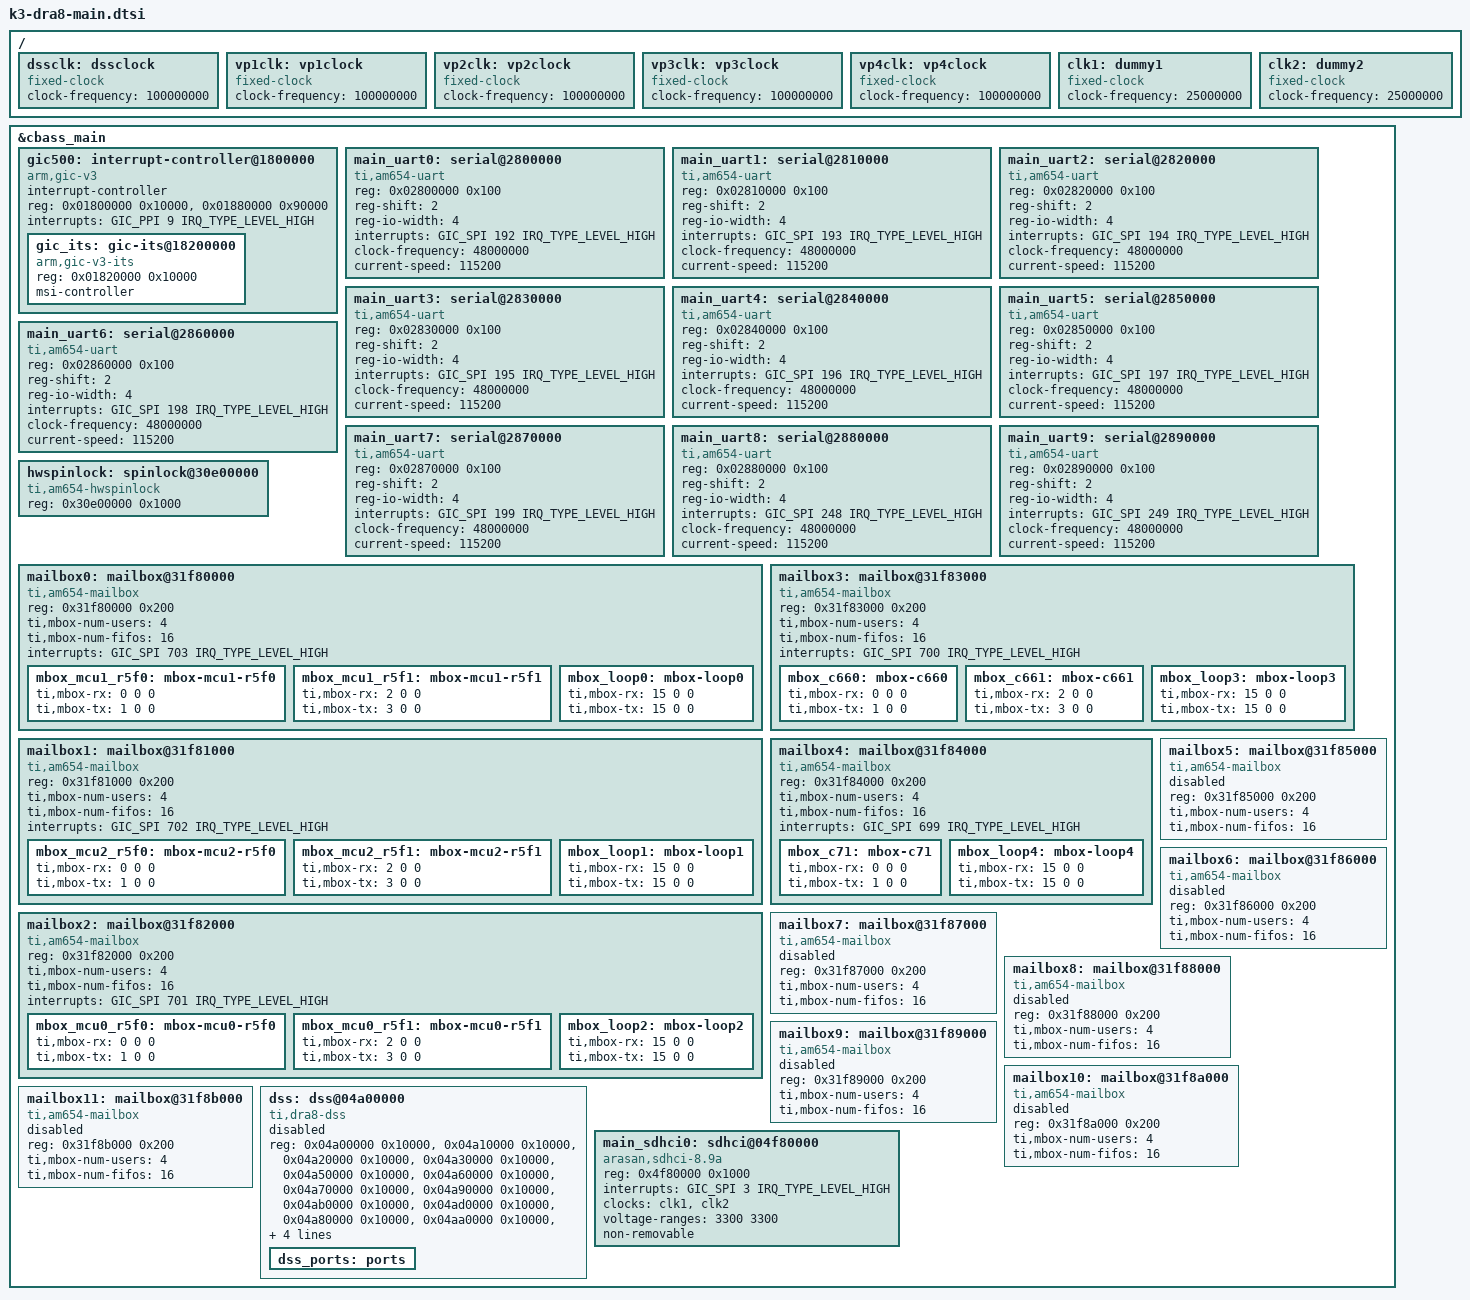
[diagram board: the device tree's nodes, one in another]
// SPDX-License-Identifier: GPL-2.0
/*
 * Device Tree Source for DRA8 SoC Family Main Domain peripherals
 *
 * Copyright (C) 2016-2018 Texas Instruments Incorporated - http://www.ti.com/
 */

/ {
	dssclk: dssclock {
		compatible = "fixed-clock";
		#clock-cells = <0>;
		clock-frequency = <100000000>;
	};

	vp1clk: vp1clock {
		compatible = "fixed-clock";
		#clock-cells = <0>;
		clock-frequency = <100000000>;
	};

	vp2clk: vp2clock {
		compatible = "fixed-clock";
		#clock-cells = <0>;
		clock-frequency = <100000000>;
	};

	vp3clk: vp3clock {
		compatible = "fixed-clock";
		#clock-cells = <0>;
		clock-frequency = <100000000>;
	};

	vp4clk: vp4clock {
		compatible = "fixed-clock";
		#clock-cells = <0>;
		clock-frequency = <100000000>;
	};

	clk1: dummy1 {
		compatible = "fixed-clock";
		#clock-cells = <0>;
		clock-frequency = <25000000>;
	};

	clk2: dummy2 {
		compatible = "fixed-clock";
		#clock-cells = <0>;
		clock-frequency = <25000000>;
	};
};

&cbass_main {
	gic500: interrupt-controller@1800000 {
		compatible = "arm,gic-v3";
		#address-cells = <1>;
		#size-cells = <1>;
		ranges;
		#interrupt-cells = <3>;
		interrupt-controller;
		reg = <0x01800000 0x10000>,	/* GICD */
		      <0x01880000 0x90000>;	/* GICR */
		/*
		 * vcpumntirq:
		 * virtual CPU interface maintenance interrupt
		 */
		interrupts = <GIC_PPI 9 IRQ_TYPE_LEVEL_HIGH>;

		gic_its: gic-its@18200000 {
			compatible = "arm,gic-v3-its";
			reg = <0x01820000 0x10000>;
			msi-controller;
			#msi-cells = <1>;
		};
	};

	main_uart0: serial@2800000 {
		compatible = "ti,am654-uart";
		reg = <0x02800000 0x100>;
		reg-shift = <2>;
		reg-io-width = <4>;
		interrupts = <GIC_SPI 192 IRQ_TYPE_LEVEL_HIGH>;
		clock-frequency = <48000000>;
		current-speed = <115200>;
	};

	main_uart1: serial@2810000 {
		compatible = "ti,am654-uart";
		reg = <0x02810000 0x100>;
		reg-shift = <2>;
		reg-io-width = <4>;
		interrupts = <GIC_SPI 193 IRQ_TYPE_LEVEL_HIGH>;
		clock-frequency = <48000000>;
		current-speed = <115200>;
	};

	main_uart2: serial@2820000 {
		compatible = "ti,am654-uart";
		reg = <0x02820000 0x100>;
		reg-shift = <2>;
		reg-io-width = <4>;
		interrupts = <GIC_SPI 194 IRQ_TYPE_LEVEL_HIGH>;
		clock-frequency = <48000000>;
		current-speed = <115200>;
	};

	main_uart3: serial@2830000 {
		compatible = "ti,am654-uart";
		reg = <0x02830000 0x100>;
		reg-shift = <2>;
		reg-io-width = <4>;
		interrupts = <GIC_SPI 195 IRQ_TYPE_LEVEL_HIGH>;
		clock-frequency = <48000000>;
		current-speed = <115200>;
	};

	main_uart4: serial@2840000 {
		compatible = "ti,am654-uart";
		reg = <0x02840000 0x100>;
		reg-shift = <2>;
		reg-io-width = <4>;
		interrupts = <GIC_SPI 196 IRQ_TYPE_LEVEL_HIGH>;
		clock-frequency = <48000000>;
		current-speed = <115200>;
	};

	main_uart5: serial@2850000 {
		compatible = "ti,am654-uart";
		reg = <0x02850000 0x100>;
		reg-shift = <2>;
		reg-io-width = <4>;
		interrupts = <GIC_SPI 197 IRQ_TYPE_LEVEL_HIGH>;
		clock-frequency = <48000000>;
		current-speed = <115200>;
	};

	main_uart6: serial@2860000 {
		compatible = "ti,am654-uart";
		reg = <0x02860000 0x100>;
		reg-shift = <2>;
		reg-io-width = <4>;
		interrupts = <GIC_SPI 198 IRQ_TYPE_LEVEL_HIGH>;
		clock-frequency = <48000000>;
		current-speed = <115200>;
	};

	main_uart7: serial@2870000 {
		compatible = "ti,am654-uart";
		reg = <0x02870000 0x100>;
		reg-shift = <2>;
		reg-io-width = <4>;
		interrupts = <GIC_SPI 199 IRQ_TYPE_LEVEL_HIGH>;
		clock-frequency = <48000000>;
		current-speed = <115200>;
	};

	main_uart8: serial@2880000 {
		compatible = "ti,am654-uart";
		reg = <0x02880000 0x100>;
		reg-shift = <2>;
		reg-io-width = <4>;
		interrupts = <GIC_SPI 248 IRQ_TYPE_LEVEL_HIGH>;
		clock-frequency = <48000000>;
		current-speed = <115200>;
	};

	main_uart9: serial@2890000 {
		compatible = "ti,am654-uart";
		reg = <0x02890000 0x100>;
		reg-shift = <2>;
		reg-io-width = <4>;
		interrupts = <GIC_SPI 249 IRQ_TYPE_LEVEL_HIGH>;
		clock-frequency = <48000000>;
		current-speed = <115200>;
	};

	hwspinlock: spinlock@30e00000 {
		compatible = "ti,am654-hwspinlock";
		reg = <0x30e00000 0x1000>;
		#hwlock-cells = <1>;
	};

	mailbox0: mailbox@31f80000 {
		compatible = "ti,am654-mailbox";
		reg = <0x31f80000 0x200>;
		#mbox-cells = <1>;
		ti,mbox-num-users = <4>;
		ti,mbox-num-fifos = <16>;
		/* NAVSS512_IR_IN_498 -> NAVSS512_IR_OUT_191 -> GIC_SPI_735 */
		interrupts = <GIC_SPI 703 IRQ_TYPE_LEVEL_HIGH>;

		mbox_mcu1_r5f0: mbox-mcu1-r5f0 {
			ti,mbox-rx = <0 0 0>;
			ti,mbox-tx = <1 0 0>;
		};

		mbox_mcu1_r5f1: mbox-mcu1-r5f1 {
			ti,mbox-rx = <2 0 0>;
			ti,mbox-tx = <3 0 0>;
		};

		mbox_loop0: mbox-loop0 {
			ti,mbox-rx = <15 0 0>;
			ti,mbox-tx = <15 0 0>;
		};
	};

	mailbox1: mailbox@31f81000 {
		compatible = "ti,am654-mailbox";
		reg = <0x31f81000 0x200>;
		#mbox-cells = <1>;
		ti,mbox-num-users = <4>;
		ti,mbox-num-fifos = <16>;
		/* NAVSS512_IR_IN_494 -> NAVSS512_IR_OUT_190 -> GIC_SPI_734 */
		interrupts = <GIC_SPI 702 IRQ_TYPE_LEVEL_HIGH>;

		mbox_mcu2_r5f0: mbox-mcu2-r5f0 {
			ti,mbox-rx = <0 0 0>;
			ti,mbox-tx = <1 0 0>;
		};

		mbox_mcu2_r5f1: mbox-mcu2-r5f1 {
			ti,mbox-rx = <2 0 0>;
			ti,mbox-tx = <3 0 0>;
		};

		mbox_loop1: mbox-loop1 {
			ti,mbox-rx = <15 0 0>;
			ti,mbox-tx = <15 0 0>;
		};
	};

	mailbox2: mailbox@31f82000 {
		compatible = "ti,am654-mailbox";
		reg = <0x31f82000 0x200>;
		#mbox-cells = <1>;
		ti,mbox-num-users = <4>;
		ti,mbox-num-fifos = <16>;
		/* NAVSS512_IR_IN_490 -> NAVSS512_IR_OUT_189 -> GIC_SPI_733 */
		interrupts = <GIC_SPI 701 IRQ_TYPE_LEVEL_HIGH>;

		mbox_mcu0_r5f0: mbox-mcu0-r5f0 {
			ti,mbox-rx = <0 0 0>;
			ti,mbox-tx = <1 0 0>;
		};

		mbox_mcu0_r5f1: mbox-mcu0-r5f1 {
			ti,mbox-rx = <2 0 0>;
			ti,mbox-tx = <3 0 0>;
		};

		mbox_loop2: mbox-loop2 {
			ti,mbox-rx = <15 0 0>;
			ti,mbox-tx = <15 0 0>;
		};
	};

	mailbox3: mailbox@31f83000 {
		compatible = "ti,am654-mailbox";
		reg = <0x31f83000 0x200>;
		#mbox-cells = <1>;
		ti,mbox-num-users = <4>;
		ti,mbox-num-fifos = <16>;
		/* NAVSS512_IR_IN_486 -> NAVSS512_IR_OUT_188 -> GIC_SPI_732 */
		interrupts = <GIC_SPI 700 IRQ_TYPE_LEVEL_HIGH>;

		mbox_c660: mbox-c660 {
			ti,mbox-rx = <0 0 0>;
			ti,mbox-tx = <1 0 0>;
		};

		mbox_c661: mbox-c661 {
			ti,mbox-rx = <2 0 0>;
			ti,mbox-tx = <3 0 0>;
		};

		mbox_loop3: mbox-loop3 {
			ti,mbox-rx = <15 0 0>;
			ti,mbox-tx = <15 0 0>;
		};
	};

	mailbox4: mailbox@31f84000 {
		compatible = "ti,am654-mailbox";
		reg = <0x31f84000 0x200>;
		#mbox-cells = <1>;
		ti,mbox-num-users = <4>;
		ti,mbox-num-fifos = <16>;
		/* NAVSS512_IR_IN_482 -> NAVSS512_IR_OUT_187 -> GIC_SPI_731 */
		interrupts = <GIC_SPI 699 IRQ_TYPE_LEVEL_HIGH>;

		mbox_c71: mbox-c71 {
			ti,mbox-rx = <0 0 0>;
			ti,mbox-tx = <1 0 0>;
		};

		mbox_loop4: mbox-loop4 {
			ti,mbox-rx = <15 0 0>;
			ti,mbox-tx = <15 0 0>;
		};
	};

	mailbox5: mailbox@31f85000 {
		compatible = "ti,am654-mailbox";
		reg = <0x31f85000 0x200>;
		#mbox-cells = <1>;
		ti,mbox-num-users = <4>;
		ti,mbox-num-fifos = <16>;
		status = "disabled";
	};

	mailbox6: mailbox@31f86000 {
		compatible = "ti,am654-mailbox";
		reg = <0x31f86000 0x200>;
		#mbox-cells = <1>;
		ti,mbox-num-users = <4>;
		ti,mbox-num-fifos = <16>;
		status = "disabled";
	};

	mailbox7: mailbox@31f87000 {
		compatible = "ti,am654-mailbox";
		reg = <0x31f87000 0x200>;
		#mbox-cells = <1>;
		ti,mbox-num-users = <4>;
		ti,mbox-num-fifos = <16>;
		status = "disabled";
	};

	mailbox8: mailbox@31f88000 {
		compatible = "ti,am654-mailbox";
		reg = <0x31f88000 0x200>;
		#mbox-cells = <1>;
		ti,mbox-num-users = <4>;
		ti,mbox-num-fifos = <16>;
		status = "disabled";
	};

	mailbox9: mailbox@31f89000 {
		compatible = "ti,am654-mailbox";
		reg = <0x31f89000 0x200>;
		#mbox-cells = <1>;
		ti,mbox-num-users = <4>;
		ti,mbox-num-fifos = <16>;
		status = "disabled";
	};

	mailbox10: mailbox@31f8a000 {
		compatible = "ti,am654-mailbox";
		reg = <0x31f8a000 0x200>;
		#mbox-cells = <1>;
		ti,mbox-num-users = <4>;
		ti,mbox-num-fifos = <16>;
		status = "disabled";
	};

	mailbox11: mailbox@31f8b000 {
		compatible = "ti,am654-mailbox";
		reg = <0x31f8b000 0x200>;
		#mbox-cells = <1>;
		ti,mbox-num-users = <4>;
		ti,mbox-num-fifos = <16>;
		status = "disabled";
	};

	dss: dss@04a00000 {
		compatible = "ti,dra8-dss";
		reg =
			<0x04a00000 0x10000>, /* common */
			<0x04a10000 0x10000>, /* common1*/

			<0x04a20000 0x10000>, /* vidl1 */
			<0x04a30000 0x10000>, /* vidl2 */
			<0x04a50000 0x10000>, /* vid1 */
			<0x04a60000 0x10000>, /* vid2 */

			<0x04a70000 0x10000>, /* ovr1 */
			<0x04a90000 0x10000>, /* ovr2 */
			<0x04ab0000 0x10000>, /* ovr3 */
			<0x04ad0000 0x10000>, /* ovr4 */

			<0x04a80000 0x10000>, /* vp1 */
			<0x04aa0000 0x10000>, /* vp2 */
			<0x04ac0000 0x10000>, /* vp3 */
			<0x04ae0000 0x10000>, /* vp4 */
			<0x04af0000 0x10000>; /* wb */

		reg-names = "common", "common1",
			"vidl1", "vidl2","vid1","vid2",
			"ovr1", "ovr2", "ovr3", "ovr4",
			"vp1", "vp2", "vp3", "vp4",
			"wb";

		clocks = <&dssclk>, <&vp1clk>, <&vp2clk>, <&vp3clk>,
				<&vp4clk>;
		clock-names = "fck", "vp1", "vp2", "vp3", "vp4";

		interrupts = <GIC_SPI 602 IRQ_TYPE_EDGE_RISING>;

		status = "disabled";

		dss_ports: ports {
			#address-cells = <1>;
			#size-cells = <0>;
		};
	};

	main_sdhci0: sdhci@04f80000 {
		compatible = "arasan,sdhci-8.9a";
		reg = <0x4f80000 0x1000>;
		interrupts = <GIC_SPI 3 IRQ_TYPE_LEVEL_HIGH>;
		clock-names = "clk_xin", "clk_ahb";
		clocks = <&clk1>, <&clk2>;
		voltage-ranges = <3300 3300>;
		non-removable;
	};
};
